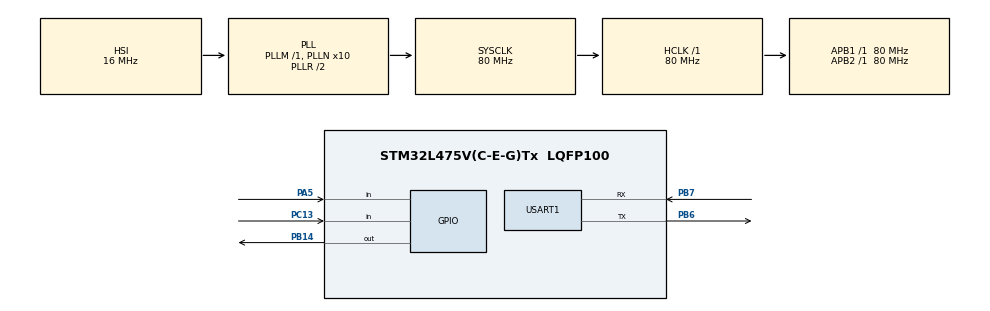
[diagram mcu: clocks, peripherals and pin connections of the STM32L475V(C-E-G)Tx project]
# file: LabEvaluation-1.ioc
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Mcu.Family=STM32L4
Mcu.Name=STM32L475V(C-E-G)Tx
Mcu.Package=LQFP100
NVIC.PriorityGroup=NVIC_PRIORITYGROUP_4
PA5.Signal=GPIO_Input
PB14.Signal=GPIO_Output
PB6.Mode=Asynchronous
PB6.Signal=USART1_TX
PB7.Mode=Asynchronous
PB7.Signal=USART1_RX
PC13.Signal=GPIO_Input
PC14-OSC32_IN\ (PC14).Mode=LSE-External-Clock-Source
PC14-OSC32_IN\ (PC14).Signal=RCC_OSC32_IN
PH0-OSC_IN\ (PH0).Mode=HSE-External-Clock-Source
PH0-OSC_IN\ (PH0).Signal=RCC_OSC_IN
ProjectManager.HeapSize=0x200
ProjectManager.StackSize=0x400
ProjectManager.TargetToolchain=STM32CubeIDE
RCC.ADCFreq_Value=64000000
RCC.AHBFreq_Value=80000000
RCC.APB1Freq_Value=80000000
RCC.APB1TimFreq_Value=80000000
RCC.APB2Freq_Value=80000000
RCC.APB2TimFreq_Value=80000000
RCC.CortexFreq_Value=80000000
RCC.HCLKFreq_Value=80000000
RCC.HSE_VALUE=8000000
RCC.HSI_VALUE=16000000
RCC.LSE_VALUE=32768
RCC.MSI_VALUE=4000000
RCC.PLLN=10
RCC.PLLSourceVirtual=RCC_PLLSOURCE_HSI
RCC.SYSCLKFreq_VALUE=80000000
RCC.SYSCLKSource=RCC_SYSCLKSOURCE_PLLCLK
RCC.USBFreq_Value=64000000
RCC.VCOOutputFreq_Value=160000000
USART1.VirtualMode-Asynchronous=VM_ASYNC
board=custom

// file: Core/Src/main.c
/* USER CODE BEGIN Header */
/**
  ******************************************************************************
  * @file           : main.c
  * @brief          : Main program body - Smart Traffic Signal Module
  ******************************************************************************
  */
/* USER CODE END Header */
#include "main.h"

/* USER CODE BEGIN Includes */
#include <string.h>
/* USER CODE END Includes */

UART_HandleTypeDef huart1;

/* USER CODE BEGIN PV */
uint8_t system_active = 0;                 // 0 = IDLE, 1 = ACTIVE
uint8_t last_button_state = GPIO_PIN_SET;  // PC13 not pressed = HIGH (on most boards)
char msg[] = "SIGNAL_ACTIVE\r\n";
/* USER CODE END PV */

void SystemClock_Config(void);
static void MX_GPIO_Init(void);
static void MX_USART1_UART_Init(void);

int main(void)
{
  HAL_Init();
  SystemClock_Config();

  MX_GPIO_Init();
  MX_USART1_UART_Init();

  /* Initial State: LED OFF */
  HAL_GPIO_WritePin(GPIOA, GPIO_PIN_5, GPIO_PIN_RESET);

  while (1)
  {
    /* Read button PC13 (usually active LOW on STM32 boards) */
    uint8_t button_state = HAL_GPIO_ReadPin(GPIOC, GPIO_PIN_13);

    /* Detect button press edge (HIGH -> LOW) */
    if (last_button_state == GPIO_PIN_SET && button_state == GPIO_PIN_RESET)
    {
      system_active = !system_active;   // Toggle system state
      HAL_Delay(200);                   // Debounce delay
    }
    last_button_state = button_state;

    if (system_active)
    {
      /* ACTIVE STATE: Blink LED at 1 Hz */

      /* LED ON */
      HAL_GPIO_WritePin(GPIOA, GPIO_PIN_5, GPIO_PIN_SET);
      HAL_Delay(500);

      /* LED OFF */
      HAL_GPIO_WritePin(GPIOA, GPIO_PIN_5, GPIO_PIN_RESET);
      HAL_Delay(500);

      /* Periodic UART message */
      HAL_UART_Transmit(&huart1, (uint8_t*)msg, strlen(msg), 500);
    }
    else
    {
      /* IDLE STATE: LED OFF, no UART transmission */
      HAL_GPIO_WritePin(GPIOA, GPIO_PIN_5, GPIO_PIN_RESET);
    }
  }
}

void SystemClock_Config(void)
{
  RCC_OscInitTypeDef RCC_OscInitStruct = {0};
  RCC_ClkInitTypeDef RCC_ClkInitStruct = {0};

  if (HAL_PWREx_ControlVoltageScaling(PWR_REGULATOR_VOLTAGE_SCALE1) != HAL_OK)
  {
    Error_Handler();
  }

  RCC_OscInitStruct.OscillatorType = RCC_OSCILLATORTYPE_HSI;
  RCC_OscInitStruct.HSIState = RCC_HSI_ON;
  RCC_OscInitStruct.HSICalibrationValue = RCC_HSICALIBRATION_DEFAULT;
  RCC_OscInitStruct.PLL.PLLState = RCC_PLL_ON;
  RCC_OscInitStruct.PLL.PLLSource = RCC_PLLSOURCE_HSI;
  RCC_OscInitStruct.PLL.PLLM = 1;
  RCC_OscInitStruct.PLL.PLLN = 10;
  RCC_OscInitStruct.PLL.PLLP = RCC_PLLP_DIV7;
  RCC_OscInitStruct.PLL.PLLQ = RCC_PLLQ_DIV2;
  RCC_OscInitStruct.PLL.PLLR = RCC_PLLR_DIV2;
  if (HAL_RCC_OscConfig(&RCC_OscInitStruct) != HAL_OK)
  {
    Error_Handler();
  }

  RCC_ClkInitStruct.ClockType = RCC_CLOCKTYPE_HCLK|RCC_CLOCKTYPE_SYSCLK
                              |RCC_CLOCKTYPE_PCLK1|RCC_CLOCKTYPE_PCLK2;
  RCC_ClkInitStruct.SYSCLKSource = RCC_SYSCLKSOURCE_PLLCLK;
  RCC_ClkInitStruct.AHBCLKDivider = RCC_SYSCLK_DIV1;
  RCC_ClkInitStruct.APB1CLKDivider = RCC_HCLK_DIV1;
  RCC_ClkInitStruct.APB2CLKDivider = RCC_HCLK_DIV1;

  if (HAL_RCC_ClockConfig(&RCC_ClkInitStruct, FLASH_LATENCY_4) != HAL_OK)
  {
    Error_Handler();
  }
}

static void MX_USART1_UART_Init(void)
{
  huart1.Instance = USART1;
  huart1.Init.BaudRate = 9600;
  huart1.Init.WordLength = UART_WORDLENGTH_8B;
  huart1.Init.StopBits = UART_STOPBITS_1;
  huart1.Init.Parity = UART_PARITY_NONE;
  huart1.Init.Mode = UART_MODE_TX_RX;
  huart1.Init.HwFlowCtl = UART_HWCONTROL_NONE;
  huart1.Init.OverSampling = UART_OVERSAMPLING_16;
  huart1.Init.OneBitSampling = UART_ONE_BIT_SAMPLE_DISABLE;
  huart1.AdvancedInit.AdvFeatureInit = UART_ADVFEATURE_NO_INIT;
  if (HAL_UART_Init(&huart1) != HAL_OK)
  {
    Error_Handler();
  }
}

static void MX_GPIO_Init(void)
{
  GPIO_InitTypeDef GPIO_InitStruct = {0};

  __HAL_RCC_GPIOC_CLK_ENABLE();
  __HAL_RCC_GPIOH_CLK_ENABLE();
  __HAL_RCC_GPIOA_CLK_ENABLE();
  __HAL_RCC_GPIOB_CLK_ENABLE();

  /* LED PA5 */
  HAL_GPIO_WritePin(GPIOA, GPIO_PIN_5, GPIO_PIN_RESET);
  GPIO_InitStruct.Pin = GPIO_PIN_5;
  GPIO_InitStruct.Mode = GPIO_MODE_OUTPUT_PP;
  GPIO_InitStruct.Pull = GPIO_NOPULL;
  GPIO_InitStruct.Speed = GPIO_SPEED_FREQ_LOW;
  HAL_GPIO_Init(GPIOA, &GPIO_InitStruct);

  /* Button PC13 */
  GPIO_InitStruct.Pin = GPIO_PIN_13;
  GPIO_InitStruct.Mode = GPIO_MODE_INPUT;
  GPIO_InitStruct.Pull = GPIO_NOPULL;   // Use NOPULL (as in your original)
  HAL_GPIO_Init(GPIOC, &GPIO_InitStruct);
}

void Error_Handler(void)
{
  __disable_irq();
  while (1)
  {
  }
}
